VERSION ""

NS_ :

BS_:

BU_: FrontCamera Tester
VAL_TABLE_ Fail_Safe_Value 5 "Full" 4 "Partial" 3 "Partial" 2 "Partial" 1 "OK" 0 "NOK" ;
VAL_TABLE_ Vision_Status 2 "Vision" 0 "Not vision." ;
VAL_TABLE_ PP_AEB_Status 2 "Fault" 1 "Available" 0 "Unavailable" ;
VAL_TABLE_ ECU_State 2 "Fail" 1 "OK" 0 "Not Present" ;
VAL_TABLE_ PP_TSR_Status 5 "Expelled" 4 "Out_Of_Image" 3 "Occluded" 2 "Partially_Occluded" 1 "Visible" 0 "Invalid" ;

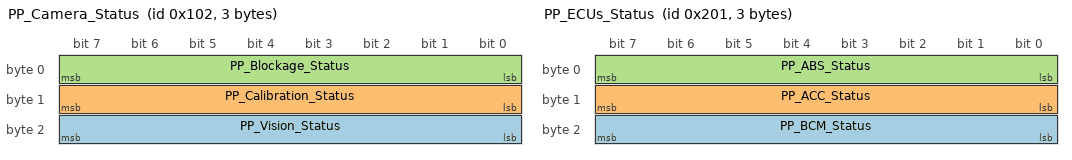
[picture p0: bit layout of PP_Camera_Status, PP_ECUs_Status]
BO_ 258 PP_Camera_Status: 3 FrontCamera
 SG_ PP_Vision_Status : 16|8@1+ (1,0) [0|0] ""  Tester
 SG_ PP_Calibration_Status : 8|8@1+ (1,0) [0|0] ""  Tester
 SG_ PP_Blockage_Status : 0|8@1+ (1,0) [0|0] ""  Tester

BO_ 257 PP_AEB: 1 FrontCamera
 SG_ PP_AEB_Status : 0|8@1+ (1,0) [0|0] ""  Tester

BO_ 513 PP_ECUs_Status: 3 Tester
 SG_ PP_BCM_Status : 16|8@1+ (1,0) [0|0] ""  FrontCamera
 SG_ PP_ACC_Status : 8|8@1+ (1,0) [0|0] ""  FrontCamera
 SG_ PP_ABS_Status : 0|8@1+ (1,0) [0|0] ""  FrontCamera

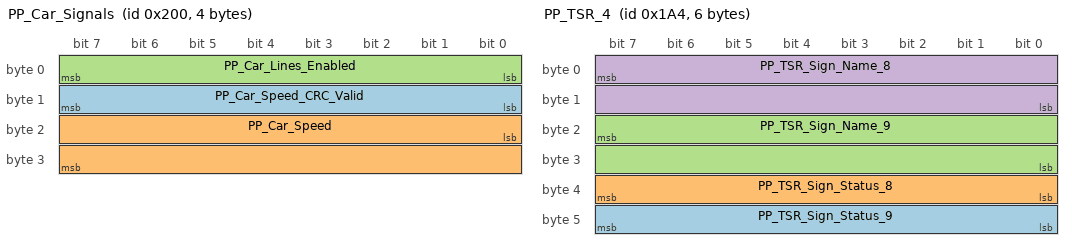
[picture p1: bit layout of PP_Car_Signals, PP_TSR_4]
BO_ 512 PP_Car_Signals: 4 Tester
 SG_ PP_Car_Speed_CRC_Valid : 8|8@1+ (1,0) [0|0] ""  Tester,FrontCamera
 SG_ PP_Car_Speed : 16|16@1+ (1,0) [0|250] ""  Tester,FrontCamera
 SG_ PP_Car_Lines_Enabled : 0|8@1+ (1,0) [0|0] ""  Tester,FrontCamera

BO_ 420 PP_TSR_4: 6 FrontCamera
 SG_ PP_TSR_Sign_Status_9 : 47|8@0+ (1,0) [0|0] ""  Tester
 SG_ PP_TSR_Sign_Status_8 : 39|8@0+ (1,0) [0|0] ""  Tester
 SG_ PP_TSR_Sign_Name_9 : 23|16@0+ (1,0) [0|0] ""  Tester
 SG_ PP_TSR_Sign_Name_8 : 7|16@0+ (1,0) [0|0] ""  Tester

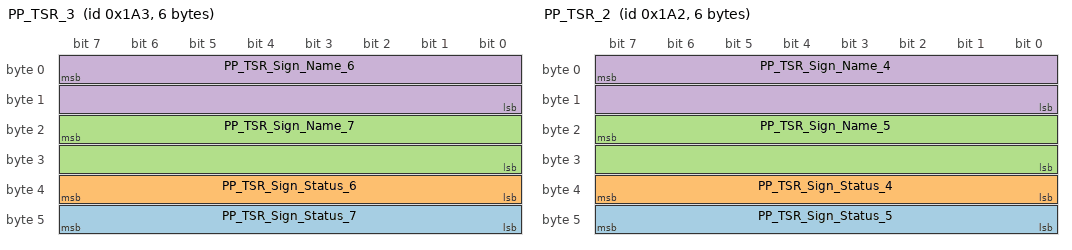
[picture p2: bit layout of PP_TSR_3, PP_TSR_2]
BO_ 419 PP_TSR_3: 6 FrontCamera
 SG_ PP_TSR_Sign_Status_7 : 47|8@0+ (1,0) [0|0] ""  Tester
 SG_ PP_TSR_Sign_Status_6 : 39|8@0+ (1,0) [0|0] ""  Tester
 SG_ PP_TSR_Sign_Name_7 : 23|16@0+ (1,0) [0|0] ""  Tester
 SG_ PP_TSR_Sign_Name_6 : 7|16@0+ (1,0) [0|0] ""  Tester

BO_ 418 PP_TSR_2: 6 FrontCamera
 SG_ PP_TSR_Sign_Status_5 : 47|8@0+ (1,0) [0|0] ""  Tester
 SG_ PP_TSR_Sign_Status_4 : 39|8@0+ (1,0) [0|0] ""  Tester
 SG_ PP_TSR_Sign_Name_5 : 23|16@0+ (1,0) [0|0] ""  Tester
 SG_ PP_TSR_Sign_Name_4 : 7|16@0+ (1,0) [0|0] ""  Tester

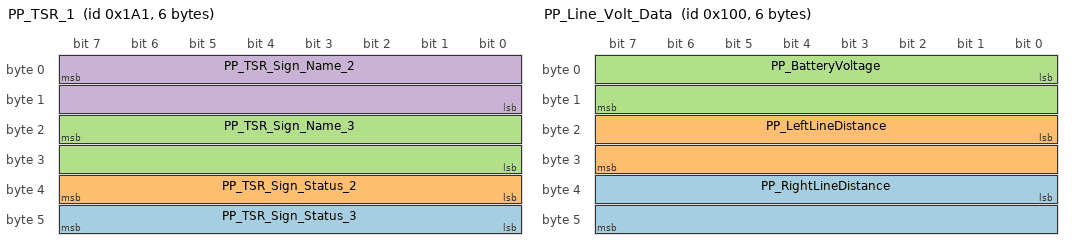
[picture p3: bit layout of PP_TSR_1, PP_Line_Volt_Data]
BO_ 417 PP_TSR_1: 6 FrontCamera
 SG_ PP_TSR_Sign_Status_3 : 47|8@0+ (1,0) [0|0] ""  Tester
 SG_ PP_TSR_Sign_Status_2 : 39|8@0+ (1,0) [0|0] ""  Tester
 SG_ PP_TSR_Sign_Name_3 : 23|16@0+ (1,0) [0|0] ""  Tester
 SG_ PP_TSR_Sign_Name_2 : 7|16@0+ (1,0) [0|0] ""  Tester

BO_ 2012 DTOOL_to_FrontCamera: 8 Tester
 SG_ DTOOL_to_FrontCamera_IC : 7|64@0+ (1,0) [0|0] ""  FrontCamera

BO_ 256 PP_Line_Volt_Data: 6 FrontCamera
 SG_ PP_RightLineDistance : 32|16@1- (0.01,0) [-40|40] ""  Tester
 SG_ PP_LeftLineDistance : 16|16@1- (0.01,0) [-40|40] ""  Tester
 SG_ PP_BatteryVoltage : 0|16@1- (0.01,0) [0|32] ""  Tester

BO_ 2013 FrontCamera_to_DTOOL: 8 FrontCamera
 SG_ FrontCamera_to_DTOOL_IC : 7|64@0+ (1,0) [0|0] ""  Tester

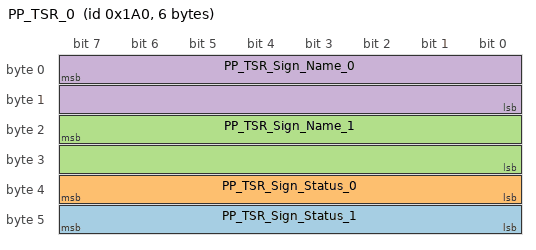
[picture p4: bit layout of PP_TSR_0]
BO_ 416 PP_TSR_0: 6 FrontCamera
 SG_ PP_TSR_Sign_Status_1 : 47|8@0+ (1,0) [0|0] ""  Tester
 SG_ PP_TSR_Sign_Status_0 : 39|8@0+ (1,0) [0|0] ""  Tester
 SG_ PP_TSR_Sign_Name_1 : 23|16@0+ (1,0) [0|0] ""  Tester
 SG_ PP_TSR_Sign_Name_0 : 7|16@0+ (1,0) [0|0] ""  Tester

BA_DEF_ BO_  "DiagConnection" INT 0 65535;
BA_DEF_  "Manufacturer" STRING ;
BA_DEF_ BO_  "DiagResponse" ENUM  "No","Yes";
BA_DEF_ BO_  "DiagRequest" ENUM  "No","Yes";
BA_DEF_  "DBName" STRING ;
BA_DEF_ SG_  "GenSigSendType" ENUM  "Cyclic","OnWrite","OnWriteWithRepetition","OnChangeWithRepetition","OnChange","IfActive","IfActiveWithRepetition","NoSigSendType";
BA_DEF_ BO_  "GenMsgCycleTime" INT 0 10000;
BA_DEF_ BO_  "GenMsgSendType" ENUM  "Cyclic","Cyclic+Event","Event","NotClear","NoMsgSendType","Other","Periodic and Event";
BA_DEF_ BO_  "GenMsgILSupport" ENUM  "no","yes";
BA_DEF_  "BusType" STRING ;
BA_DEF_ BO_  "CycleTime" INT 0 10000;
BA_DEF_ BO_  "FrameType" STRING ;
BA_DEF_DEF_  "DiagConnection" 0;
BA_DEF_DEF_  "Manufacturer" "Vector";
BA_DEF_DEF_  "DiagResponse" "No";
BA_DEF_DEF_  "DiagRequest" "No";
BA_DEF_DEF_  "DBName" "VEHICLE_CAN";
BA_DEF_DEF_  "GenSigSendType" "Cyclic";
BA_DEF_DEF_  "GenMsgCycleTime" 0;
BA_DEF_DEF_  "GenMsgSendType" "Cyclic";
BA_DEF_DEF_  "GenMsgILSupport" "yes";
BA_DEF_DEF_  "BusType" "CAN";
BA_DEF_DEF_  "CycleTime" 100;
BA_DEF_DEF_  "FrameType" "-";
BA_ "GenMsgCycleTime" BO_ 258 100;
BA_ "GenMsgCycleTime" BO_ 257 100;
BA_ "GenMsgCycleTime" BO_ 513 100;
BA_ "GenMsgCycleTime" BO_ 512 100;
BA_ "FrameType" BO_ 420 "Periodic and Event";
BA_ "GenMsgCycleTime" BO_ 420 100;
BA_ "FrameType" BO_ 419 "Periodic and Event";
BA_ "GenMsgCycleTime" BO_ 419 100;
BA_ "FrameType" BO_ 418 "Periodic and Event";
BA_ "GenMsgCycleTime" BO_ 418 100;
BA_ "FrameType" BO_ 417 "Periodic and Event";
BA_ "GenMsgCycleTime" BO_ 417 100;
BA_ "DiagRequest" BO_ 2012 1;
BA_ "FrameType" BO_ 2012 "Diagnostic";
BA_ "DiagConnection" BO_ 2012 57345;
BA_ "GenMsgSendType" BO_ 2012 5;
BA_ "CycleTime" BO_ 2012 0;
BA_ "GenMsgCycleTime" BO_ 256 60;
BA_ "FrameType" BO_ 256 "Periodic";
BA_ "CycleTime" BO_ 256 60;
BA_ "DiagResponse" BO_ 2013 1;
BA_ "FrameType" BO_ 2013 "Diagnostic";
BA_ "DiagConnection" BO_ 2013 57345;
BA_ "GenMsgSendType" BO_ 2013 4;
BA_ "CycleTime" BO_ 2013 0;
BA_ "FrameType" BO_ 416 "Periodic and Event";
BA_ "GenMsgCycleTime" BO_ 416 100;
BA_ "GenSigSendType" SG_ 2012 DTOOL_to_FrontCamera_IC 7;
BA_ "GenSigSendType" SG_ 2013 FrontCamera_to_DTOOL_IC 7;
VAL_ 258 PP_Vision_Status 2 "Vision" 0 "Not vision." ;
VAL_ 258 PP_Calibration_Status 5 "Full" 4 "Partial" 3 "Partial" 2 "Partial" 1 "OK" 0 "NOK" ;
VAL_ 258 PP_Blockage_Status 5 "Full" 4 "Partial" 3 "Partial" 2 "Partial" 1 "OK" 0 "NOK" ;
VAL_ 257 PP_AEB_Status 2 "Fault" 1 "Available" 0 "Unavailable" ;
VAL_ 513 PP_BCM_Status 2 "Fail" 1 "OK" 0 "Not Present" ;
VAL_ 513 PP_ACC_Status 2 "Fail" 1 "OK" 0 "Not Present" ;
VAL_ 513 PP_ABS_Status 2 "Fail" 1 "OK" 0 "Not Present" ;
VAL_ 420 PP_TSR_Sign_Status_9 5 "Expelled" 4 "Out_Of_Image" 3 "Occluded" 2 "Partially_Occluded" 1 "Visible" 0 "Invalid" ;
VAL_ 420 PP_TSR_Sign_Status_8 5 "Expelled" 4 "Out_Of_Image" 3 "Occluded" 2 "Partially_Occluded" 1 "Visible" 0 "Invalid" ;
VAL_ 419 PP_TSR_Sign_Status_7 5 "Expelled" 4 "Out_Of_Image" 3 "Occluded" 2 "Partially_Occluded" 1 "Visible" 0 "Invalid" ;
VAL_ 419 PP_TSR_Sign_Status_6 5 "Expelled" 4 "Out_Of_Image" 3 "Occluded" 2 "Partially_Occluded" 1 "Visible" 0 "Invalid" ;
VAL_ 418 PP_TSR_Sign_Status_5 5 "Expelled" 4 "Out_Of_Image" 3 "Occluded" 2 "Partially_Occluded" 1 "Visible" 0 "Invalid" ;
VAL_ 418 PP_TSR_Sign_Status_4 5 "Expelled" 4 "Out_Of_Image" 3 "Occluded" 2 "Partially_Occluded" 1 "Visible" 0 "Invalid" ;
VAL_ 417 PP_TSR_Sign_Status_3 5 "Expelled" 4 "Out_Of_Image" 3 "Occluded" 2 "Partially_Occluded" 1 "Visible" 0 "Invalid" ;
VAL_ 417 PP_TSR_Sign_Status_2 5 "Expelled" 4 "Out_Of_Image" 3 "Occluded" 2 "Partially_Occluded" 1 "Visible" 0 "Invalid" ;
VAL_ 416 PP_TSR_Sign_Status_1 5 "Expelled" 4 "Out_Of_Image" 3 "Occluded" 2 "Partially_Occluded" 1 "Visible" 0 "Invalid" ;
VAL_ 416 PP_TSR_Sign_Status_0 5 "Expelled" 4 "Out_Of_Image" 3 "Occluded" 2 "Partially_Occluded" 1 "Visible" 0 "Invalid" ;
